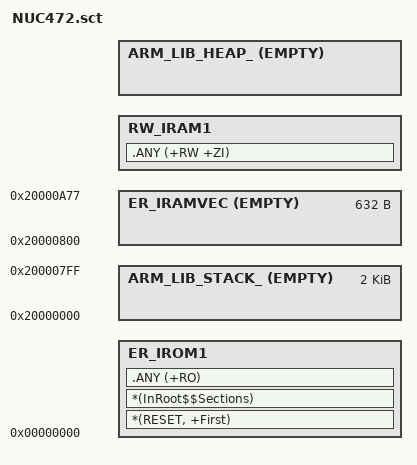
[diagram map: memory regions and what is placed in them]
#! armcc -E

#if !defined(MBED_APP_START)
  #define MBED_APP_START 0x00000000
#endif

#if !defined(MBED_APP_SIZE)
  #define MBED_APP_SIZE 0x00080000
#endif

/* If ARM_LIB_STACK/ARM_LIB_HEAP sections are defined, we cannot override __user_setup_stackheap.
 * Otherwise, we would fail in C run-time initialization with RTOS-less build. Because __user_setup_stackheap
 * has been re-implemented in platform/mbed_retarget.cpp, we rename ARM_LIB_STACK/ARM_LIB_HEAP to 
 * ARM_LIB_STACK_/ARM_LIB_HEAP_ to avoid such error. */

LR_IROM1 MBED_APP_START {
  ER_IROM1 MBED_APP_START {  ; load address = execution address
   *(RESET, +First)
   *(InRoot$$Sections)
   .ANY (+RO)
  }
  
  ;UVISOR AlignExpr(+0, 16) {  ; 16 byte-aligned
  ;  uvisor-lib.a (+RW +ZI)
  ;}
  
  ARM_LIB_STACK_ 0x20000000 EMPTY 0x800 {
  }
  
  ER_IRAMVEC 0x20000800 EMPTY (4*(16 + 142)) {  ; Reserve for vectors
  }
  
  RW_IRAM1 AlignExpr(+0, 16) {  ; 16 byte-aligned
   .ANY (+RW +ZI)
  }
  
  ; Extern SRAM for HEAP
  ARM_LIB_HEAP_ AlignExpr(+0, 16) EMPTY (0x20000000 + 0x10000 - AlignExpr(ImageLimit(RW_IRAM1), 16)) {
  }
}
ScatterAssert(LoadLimit(LR_IROM1) <= (MBED_APP_START + MBED_APP_SIZE))    ; 512 KB APROM
ScatterAssert(ImageLimit(RW_IRAM1) <= 0x20010000)   ; 64 KB SRAM (internal)

